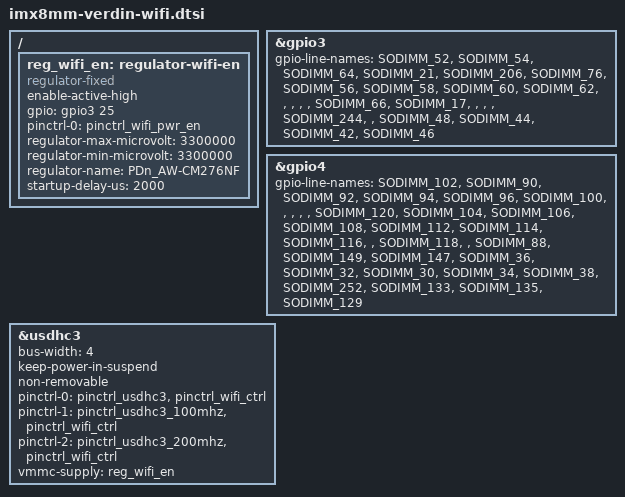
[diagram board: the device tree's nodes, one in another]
// SPDX-License-Identifier: GPL-2.0-or-later OR MIT
/*
 * Copyright 2022 Toradex
 */

/ {
	reg_wifi_en: regulator-wifi-en {
		compatible = "regulator-fixed";
		enable-active-high;
		gpio = <&gpio3 25 GPIO_ACTIVE_HIGH>;
		pinctrl-names = "default";
		pinctrl-0 = <&pinctrl_wifi_pwr_en>;
		regulator-max-microvolt = <3300000>;
		regulator-min-microvolt = <3300000>;
		regulator-name = "PDn_AW-CM276NF";
		startup-delay-us = <2000>;
	};
};

&gpio3 {
	gpio-line-names = "SODIMM_52",
			  "SODIMM_54",
			  "SODIMM_64",
			  "SODIMM_21",
			  "SODIMM_206",
			  "SODIMM_76",
			  "SODIMM_56",
			  "SODIMM_58",
			  "SODIMM_60",
			  "SODIMM_62",
			  "",
			  "",
			  "",
			  "",
			  "SODIMM_66",
			  "SODIMM_17",
			  "",
			  "",
			  "",
			  "SODIMM_244",
			  "",
			  "SODIMM_48",
			  "SODIMM_44",
			  "SODIMM_42",
			  "SODIMM_46";
};

&gpio4 {
	gpio-line-names = "SODIMM_102",
			  "SODIMM_90",
			  "SODIMM_92",
			  "SODIMM_94",
			  "SODIMM_96",
			  "SODIMM_100",
			  "",
			  "",
			  "",
			  "",
			  "SODIMM_120",
			  "SODIMM_104",
			  "SODIMM_106",
			  "SODIMM_108",
			  "SODIMM_112",
			  "SODIMM_114",
			  "SODIMM_116",
			  "",
			  "SODIMM_118",
			  "",
			  "SODIMM_88",
			  "SODIMM_149",
			  "SODIMM_147",
			  "SODIMM_36",
			  "SODIMM_32",
			  "SODIMM_30",
			  "SODIMM_34",
			  "SODIMM_38",
			  "SODIMM_252",
			  "SODIMM_133",
			  "SODIMM_135",
			  "SODIMM_129";
};

/* On-module Wi-Fi */
&usdhc3 {
	bus-width = <4>;
	keep-power-in-suspend;
	non-removable;
	pinctrl-names = "default", "state_100mhz", "state_200mhz";
	pinctrl-0 = <&pinctrl_usdhc3>, <&pinctrl_wifi_ctrl>;
	pinctrl-1 = <&pinctrl_usdhc3_100mhz>, <&pinctrl_wifi_ctrl>;
	pinctrl-2 = <&pinctrl_usdhc3_200mhz>, <&pinctrl_wifi_ctrl>;
	vmmc-supply = <&reg_wifi_en>;
	status = "okay";
};
